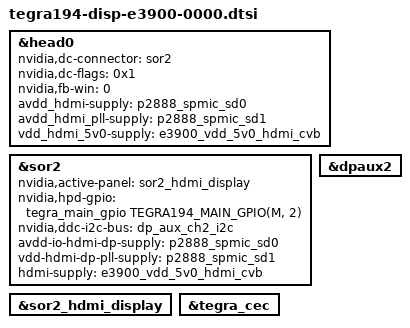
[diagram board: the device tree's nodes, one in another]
/*
 * tegra194-e3900-disp.dtsi:
 *
 * Copyright (c) 2020, NVIDIA CORPORATION.  All rights reserved.
 *
 * This program is free software; you can redistribute it and/or modify
 * it under the terms of the GNU General Public License as published by
 * the Free Software Foundation; version 2 of the License.
 *
 * This program is distributed in the hope that it will be useful, but WITHOUT
 * ANY WARRANTY; without even the implied warranty of MERCHANTABILITY or
 * FITNESS FOR A PARTICULAR PURPOSE.  See the GNU General Public License for
 * more details.
 *
 *
 * T194 McCoy uses only one display head out of the 4 available on T194:
 *	fb0: Head0->SOR2->HDMI
 * All six windows are assigned to this head.
 */

#include "tegra194-fixed-regulator-e3900-0000.dtsi"
#include "galen/kernel-dts/common/tegra194-spmic-p2888-0001.dtsi"

&head0 {
	status = "okay";
	nvidia,dc-connector = <&sor2>; // nvdisp-init only
	nvidia,dc-flags = <0x1>; // nvdisp-init only
	nvidia,fb-win = <0>; // nvdisp-init only
	avdd_hdmi-supply = <&p2888_spmic_sd0>; /* 1v0 */ // nvdisp-init only
	avdd_hdmi_pll-supply = <&p2888_spmic_sd1>; /* 1v8 */ // nvdisp-init only
	vdd_hdmi_5v0-supply = <&e3900_vdd_5v0_hdmi_cvb>; /* 5v0 */ // nvdisp-init only
};

&sor2 {
	status = "okay";
	nvidia,active-panel = <&sor2_hdmi_display>;
	nvidia,hpd-gpio = <&tegra_main_gpio TEGRA194_MAIN_GPIO(M, 2) GPIO_ACTIVE_HIGH>;
	nvidia,ddc-i2c-bus = <&dp_aux_ch2_i2c>;
	avdd-io-hdmi-dp-supply = <&p2888_spmic_sd0>; /* 1v0 */
	vdd-hdmi-dp-pll-supply = <&p2888_spmic_sd1>; /* 1v8 */
	hdmi-supply = <&e3900_vdd_5v0_hdmi_cvb>; /* 5v0 */
};

&sor2_hdmi_display {
	status = "okay";
};

&dpaux2 {
	status = "okay";
};

&tegra_cec {
	status = "okay";
};
